# GD32W515Px register map
File version: 1.0
CPU: CM33 r0p0, little endian, MPU, FPU, 4 interrupt priority bits
Registers are 32-bit, read-write, reset 0x0 unless marked. A register's access mark holds for its fields unless they carry their own. Offsets are from the block's base; [hi:lo] are bit positions; {n}, {i} and the like mark numbered series.

## TIMER5 — Basic-timers
Base 0x40001000
Same registers: SEC_TIMER5 0x50001000
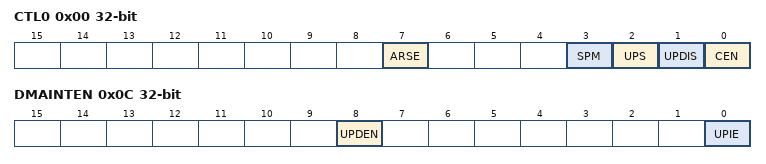
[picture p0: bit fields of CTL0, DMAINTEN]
0x00 CTL0 — control register 0
  [7] ARSE — Auto-reload preload enable
  [3] SPM — One-pulse mode
  [2] UPS — Update request source
  [1] UPDIS — Update disable
  [0] CEN — Counter enable
0x04 CTL1 — control register 1
  [6:4] MMC — Master mode selection
0x0C DMAINTEN — DMA/Interrupt enable register
  [8] UPDEN — Update DMA request enable
  [0] UPIE — Update interrupt enable
0x10 INTF — status register
  [0] UPIF — Update interrupt flag
0x14 SWEVG wo — event generation register
  [0] UPG — Update generation
0x24 CNT — counter
  [15:0] CNT — Low counter value
0x28 PSC — prescaler
  [15:0] PSC — Prescaler value
0x2C CAR — auto-reload register
  [15:0] CARL — Low Auto-reload value

## CAU — Cryptographic acceleration unit
Base 0x4C060000
Same registers: SEC_CAU 0x5C060000
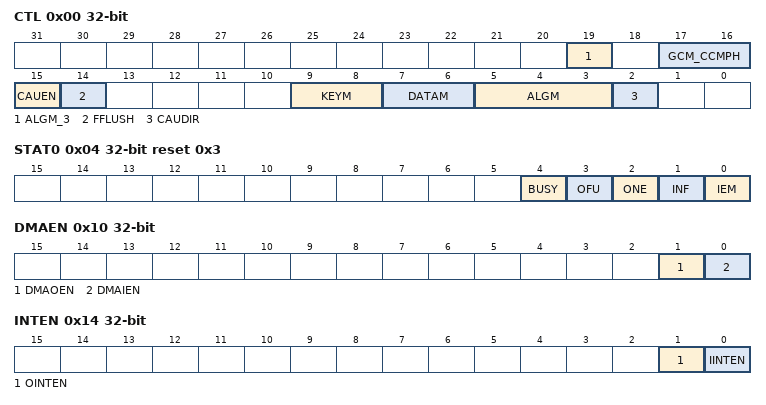
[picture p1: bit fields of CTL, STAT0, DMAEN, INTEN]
0x00 CTL access per field — CAU control register
  [19] ALGM_3 rw — Encryption/decryption algorithm mode bit 3
  [17:16] GCM_CCMPH rw — GCM CCM phase
  [15] CAUEN rw — Cryptographic module enable
  [14] FFLUSH wo — FIFO flush
  [9:8] KEYM rw — AES key size mode configuration
  [7:6] DATAM rw — Data swapping type mode configuration
  [5:3] ALGM rw — Encryption/decryption algorithm mode
  [2] CAUDIR rw — CAU direction
0x04 STAT0 ro reset 0x3 — CAU status register 0
  [4] BUSY — BUSY flag
  [3] OFU — OUT FIFO full flag
  [2] ONE — OUT FIFO not empty flag
  [1] INF — IN FIFO not full flag
  [0] IEM — IN FIFO empty flag
0x08 DI — CAU data input register
  [31:0] DI — Data input
0x0C DO ro — CAU data output register
  [31:0] DO — Data output
0x10 DMAEN — CAU DMA enable register
  [1] DMAOEN — Out FIFO DMA enable
  [0] DMAIEN — In FIFO DMA enable
0x14 INTEN — CAU interrupt enable register
  [1] OINTEN — Out FIFO interrupt enable
  [0] IINTEN — In FIFO interrupt enable
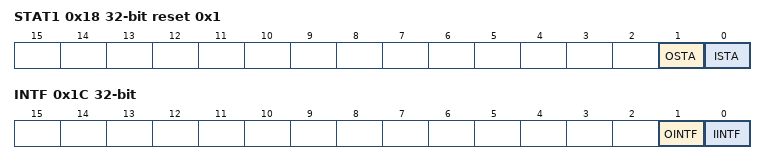
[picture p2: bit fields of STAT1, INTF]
0x18 STAT1 ro reset 0x1 — CAU interrupt status flag register 1
  [1] OSTA — Out FIFO interrupt flag
  [0] ISTA — In FIFO interrupt flag
0x1C INTF ro — CAU enable interrupt status flag register
  [1] OINTF — Out FIFO enabled interrupt flag
  [0] IINTF — In FIFO enabled interrupt flag
{0x20+8i} KEY{i}H wo (i=0..3) — CAU key register
  [31:0] KEY{i}H — Key for DES,TDES,AES
{0x24+8i} KEY{i}L wo (i=0..3) — CAU key register
  [31:0] KEY{i}L — Key for DES,TDES,AES
0x40 IV0H — CAU initialization register
  [31:0] IV0H — The initialization vector for DES,TDES,AES
0x44 IV0L — CAU initialization register
  [31:0] IV0L — The initialization vector for DES,TDES,AES
0x48 IV1H — CAU initialization register
  [31:0] IV1H — The initialization vector for DES,TDES,AES
0x4C IV1L — CAU initialization register
  [31:0] IV1L — The initialization vector for DES,TDES,AES

## DCI — Digital Camera Interface
Base 0x4C050000
Same registers: SEC_DCI 0x5C050000
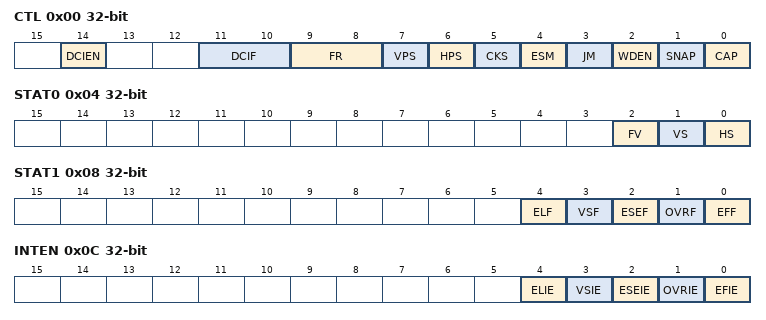
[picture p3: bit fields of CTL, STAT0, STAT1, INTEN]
0x00 CTL — Control register
  [14] DCIEN — DCI Enable
  [11:10] DCIF — Digital camera interface format
  [9:8] FR — Frame rate
  [7] VPS — Vertical Polarity Selection
  [6] HPS — Horizontal Polarity Selection
  [5] CKS — Clock Polarity Selection
  [4] ESM — Embedded Synchronous Mode
  [3] JM — JPEG mode
  [2] WDEN — Window Enable
  [1] SNAP — Snapshot mode
  [0] CAP — Capture Enable
0x04 STAT0 ro — Status register 0
  [2] FV — FIFO Valid
  [1] VS — VS line status
  [0] HS — HS line status
0x08 STAT1 ro — Status register 1
  [4] ELF — End of Line Flag
  [3] VSF — Vsync Flag
  [2] ESEF — Embedded Synchronous Error Flag
  [1] OVRF — FIFO Overrun Flag
  [0] EFF — End of Frame Flag
0x0C INTEN — Interrupt enable register
  [4] ELIE — End of Line Interrupt Enable
  [3] VSIE — Vsync Interrupt Enable
  [2] ESEIE — Embedded Synchronous Error Interrupt Enable
  [1] OVRIE — FIFO Overrun Interrupt Enable
  [0] EFIE — End of Frame Interrupt Enable
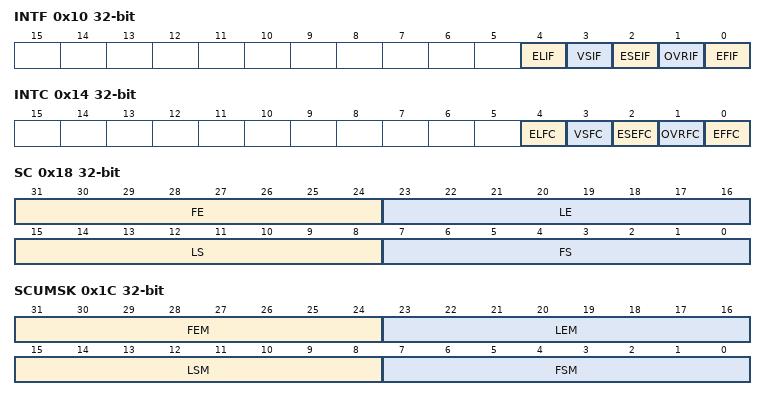
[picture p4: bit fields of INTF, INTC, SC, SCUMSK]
0x10 INTF ro — Interrupt flag register
  [4] ELIF — End of Line Interrupt Flag
  [3] VSIF — Vsync Interrupt Flag
  [2] ESEIF — Embedded Synchronous Error Interrupt Flag
  [1] OVRIF — FIFO Overrun Interrupt Flag
  [0] EFIF — End of Frame Interrupt Flag
0x14 INTC wo — Interrupt flag clear register
  [4] ELFC — End of Line Flag Clear
  [3] VSFC — Vsync flag clear
  [2] ESEFC — Clear embedded synchronous Error Flag
  [1] OVRFC — Clear FIFO Overrun Flag
  [0] EFFC — Clear End of Frame Flag
0x18 SC — Synchronization codes register
  [31:24] FE — Frame End Code in Embedded Synchronous Mode
  [23:16] LE — Line End Code in Embedded Synchronous Mode
  [15:8] LS — Line Start Code in Embedded Synchronous Mode
  [7:0] FS — Frame Start Code in Embedded Synchronous Mode
0x1C SCUMSK — Synchronization codes unmask register
  [31:24] FEM — Frame End Code unMask Bits in Embedded Synchronous Mode
  [23:16] LEM — Line End Code unMask Bits in Embedded Synchronous Mode
  [15:8] LSM — Line Start Code unMask Bits in Embedded Synchronous Mode
  [7:0] FSM — Frame Start Code unMask Bits in Embedded Synchronous Mode
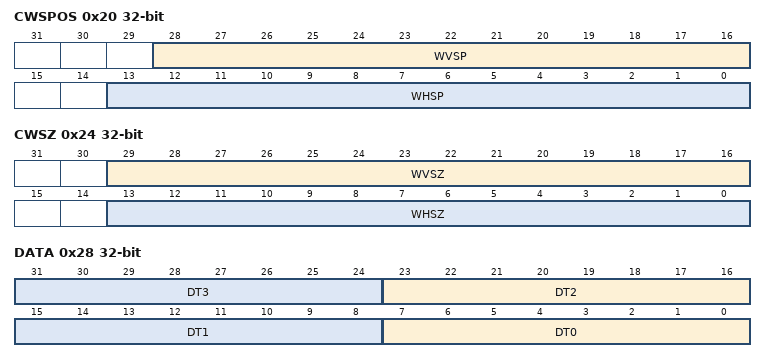
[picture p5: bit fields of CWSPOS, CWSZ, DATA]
0x20 CWSPOS — Cropping window start position register
  [28:16] WVSP — Window Vertical Start Position
  [13:0] WHSP — Window Horizontal Start Position
0x24 CWSZ — Cropping window size register
  [29:16] WVSZ — Window Vertical Size
  [13:0] WHSZ — Window Horizontal Size
0x28 DATA ro
  [8n+7:8n] DT{n} (n=0..3) — Pixel Data {n}
